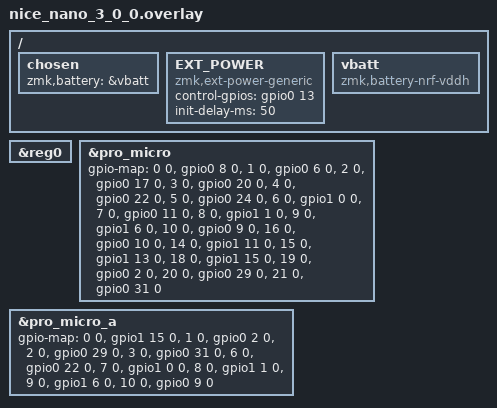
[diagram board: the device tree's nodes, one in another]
/*
 * Copyright (c) 2021 The ZMK Contributors
 *
 * SPDX-License-Identifier: MIT
 */

/ {
    chosen {
        zmk,battery = &vbatt;
    };

    // Node name must match original "EXT_POWER" label to preserve user settings.
    EXT_POWER {
        compatible = "zmk,ext-power-generic";
        control-gpios = <&gpio0 13 GPIO_ACTIVE_HIGH>;
        init-delay-ms = <50>;
    };

    vbatt: vbatt {
        compatible = "zmk,battery-nrf-vddh";
    };
};

&reg0 {
    status = "okay";
};

&pro_micro{
    gpio-map
        = <0 0 &gpio0 8 0>      /* D0 */
        , <1 0 &gpio0 6 0>      /* D1 */
        , <2 0 &gpio0 17 0>     /* D2 */
        , <3 0 &gpio0 20 0>     /* D3 */
        , <4 0 &gpio0 22 0>     /* D4/A6 */
        , <5 0 &gpio0 24 0>     /* D5 */
        , <6 0 &gpio1 0 0>      /* D6/A7 */
        , <7 0 &gpio0 11 0>     /* D7 */
        , <8 0 &gpio1 1 0>      /* D8/A8 */
        , <9 0 &gpio1 6 0>      /* D9/A9 */
        , <10 0 &gpio0 9 0>     /* D10/A10 */
        , <16 0 &gpio0 10 0>    /* D16 */
        , <14 0 &gpio1 11 0>    /* D14 */
        , <15 0 &gpio1 13 0>    /* D15 */
        , <18 0 &gpio1 15 0>    /* D18/A0 */
        , <19 0 &gpio0 2 0> /* D19/A1 */
        , <20 0 &gpio0 29 0>    /* D20/A2 */
        , <21 0 &gpio0 31 0>    /* D21/A3 */
        ;
};

&pro_micro_a {
    gpio-map
        = <0 0 &gpio1 15 0> /* D18/A0 */
        , <1 0 &gpio0 2 0>  /* D19/A1 */
        , <2 0 &gpio0 29 0> /* D20/A2 */
        , <3 0 &gpio0 31 0> /* D21/A3 */
        , <6 0 &gpio0 22 0> /* D4/A6 */
        , <7 0 &gpio1 0 0>  /* D6/A7 */
        , <8 0 &gpio1 1 0>  /* D8/A8 */
        , <9 0 &gpio1 6 0>  /* D9/A9 */
        , <10 0 &gpio0 9 0> /* D10/A10 */
        ;
};
